AUTOSAR XML (schema 00049)
package /Executables
  executable package_manager
    root sw component prototype rootSwComponentPrototype: application-type=package_manager
package /AdaptiveApplicationSwComponents
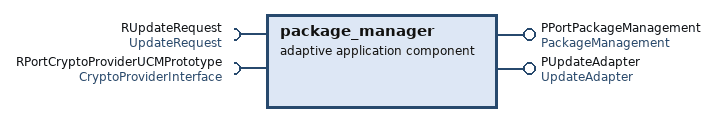
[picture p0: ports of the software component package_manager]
  adaptive application sw component type package_manager
    provide port PPortPackageManagement: provided-interface=PackageManagement
    require port RUpdateRequest: required-interface=UpdateRequest
    provide/require port SwPackageCurrentStatusPRPort: provided-required-interface=SwPackageCurrentStatus
    provide/require port SwPackageTransferStatusPRPort: provided-required-interface=SwPackageTransferStatus
    provide port PUpdateAdapter: provided-interface=UpdateAdapter
    require port RPortCryptoProviderUCMPrototype: required-interface=CryptoProviderInterface
